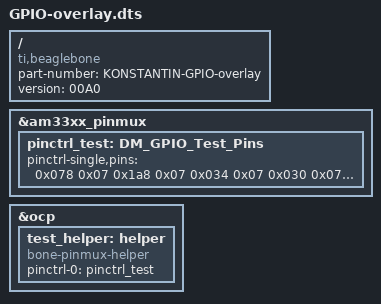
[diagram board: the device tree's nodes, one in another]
/*  
* Copyright (C) 2012 Texas Instruments Incorporated - http://www.ti.com/
*
* This program is free software; you can redistribute it and/or modify
* it under the terms of the GNU General Purpose License Version 2 as
* published by the Free Software Foundation
*
* Original from: github.com/jadonk/validation-scripts/blob/master/test-capemgr/ 
*
* Modified by  for the example on www.derekmolloy.ie
* that maps GPIO pins for the example
* 
* Modified by Konstantin to suit own usages...
*/

/dts-v1/;
/plugin/;

/{
       compatible = "ti,beaglebone", "ti,beaglebone-black";
       part-number = "KONSTANTIN-GPIO-overlay";
       version = "00A0";
       fragment@0 {
             target = <&am33xx_pinmux>;
             __overlay__ {
                  pinctrl_test: DM_GPIO_Test_Pins {
			pinctrl-single,pins = <

				0x078 0x07  /* P9_12 60 OUTPUT MODE7 - AQ Lights */
				0x1a8 0x07 /* P9_41 20 OUTPUT MODE7 - AQ Heater  */
				
				0x034 0x07  /* P8_11 45 OUTPUT MODE7 - AQ COOLER */
				0x030 0x07  /* P8_12 44 OUTPUT MODE7 - NOT IN USE = FOR GROWTH */
				0x03C 0x07  /* P8_15 47 OUTPUT MODE7 - NOT IN USE = FOR GROWTH */
	                        0x038 0x07  /* P8_16 46 OUTPUT MODE7 - NOT IN USE = FOR GROWTH */
                               /* OUTPUT  GPIO(mode7) 0x07 pulldown, 0x17 pullup, 0x?f no pullup/down */
			       /* INPUT   GPIO(mode7) 0x27 pulldown, 0x37 pullup, 0x?f no pullup/down */

			>;
		  };
             };
       };

       fragment@1 {
		target = <&ocp>;
		__overlay__ {
			test_helper: helper {
				compatible = "bone-pinmux-helper";
				pinctrl-names = "default";
				pinctrl-0 = <&pinctrl_test>;
				status = "okay";
			};
		};
	};
};
